# MCF5441x register map
Vendor: NXP; File version: 1.0
Registers are 32-bit, read-write, reset 0x0 unless marked. A register's access mark holds for its fields unless they carry their own. Offsets are from the block's base; [hi:lo] are bit positions; lines under a group give offsets from that group; {n}, {i} and the like mark numbered series.

## FLEXBUS
Base 0xFC008000
{0x0+0xC*i} CSAR{i} (i=0..5)
  [31:16] BA
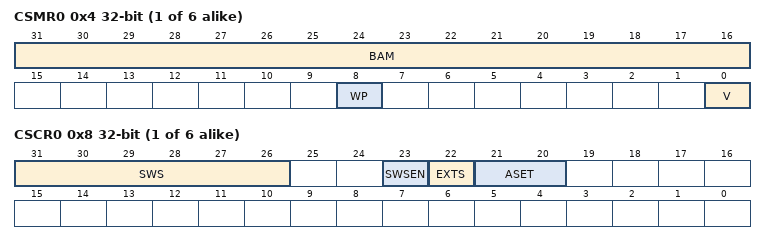
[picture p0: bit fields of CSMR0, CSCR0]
{0x4+0xC*i} CSMR{i} (i=0..5)
  [31:16] BAM
  [8] WP
  [0] V
    0=INVALID; 1=VALID
{0x8+0xC*i} CSCR{i} reset not defined (i=0..5)
  [31:26] SWS
  [23] SWSEN
  [22] EXTS
    0=ONE_CYCLE; 1=UNTIL_CS
  [21:20] ASET
    0=FIRST_EDGE; 1=SECOND_EDGE; 2=THIRD_EDGE; 3=FOURTH_EDGE

## FLEXCAN0
Base 0xFC020000
Same registers: FLEXCAN1 0xFC024000
0x00 CANMCR reset 0xD890000F
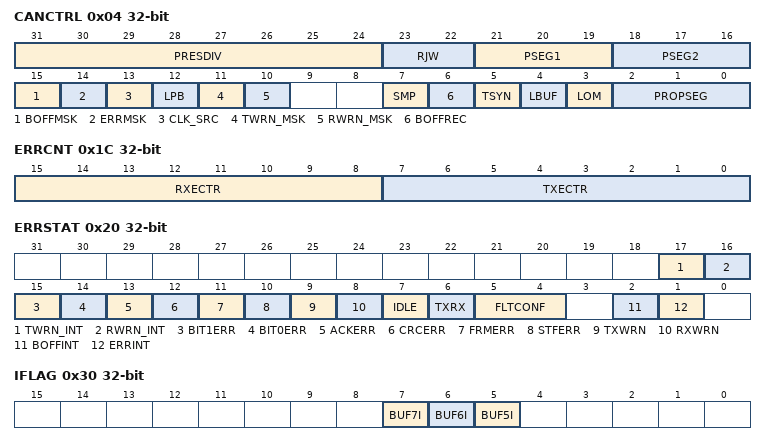
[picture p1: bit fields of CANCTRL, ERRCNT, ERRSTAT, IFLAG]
0x04 CANCTRL
  [31:24] PRESDIV
  [23:22] RJW
  [21:19] PSEG1
  [18:16] PSEG2
  [15] BOFFMSK
    0=DISABLED; 1=ENABLED
  [14] ERRMSK
    0=DISABLED; 1=ENABLED
  [13] CLK_SRC
  [12] LPB
    0=DISABLED; 1=ENABLED
  [11] TWRN_MSK
    0=DISABLED; 1=ENABLED
  [10] RWRN_MSK
    0=DISABLED; 1=ENABLED
  [7] SMP
  [6] BOFFREC
  [5] TSYN
    0=DISABLED; 1=ENABLED
  [4] LBUF
  [3] LOM
  [2:0] PROPSEG
0x08 TIMER
  [15:0] TIMER
0x10 RXGMASK reset 0x1FFFFFFF
0x14 RX14MASk reset 0x1FFFFFFF
0x18 RX15MASK reset 0x1FFFFFFF
0x1C ERRCNT
  [15:8] RXECTR, [7:0] TXECTR
0x20 ERRSTAT
  [17] TWRN_INT write-1-clears
  [16] RWRN_INT write-1-clears
  [15] BIT1ERR
  [14] BIT0ERR
  [13] ACKERR
  [12] CRCERR
  [11] FRMERR
  [10] STFERR
  [9] TXWRN
    0=TRANSMIT_ERROR_COUNTER_96; 1=TXERRCOUNTER_96
  [8] RXWRN
    0=RECEIVE_ERROR_COUNTER_96; 1=RXERRCOUNTER_96
  [7] IDLE
    0=NOT_IDLE; 1=IDLE
  [6] TXRX
  [5:4] FLTCONF
    0=ACTIVE; 1=PASSIVE
  [2] BOFFINT write-1-clears
  [1] ERRINT write-1-clears
    0=NO_ERROR; 1=ERROR
0x28 IMASK
  [15:0] BUFnM
0x30 IFLAG
  [7] BUF7I, [6] BUF6I, [5] BUF5I
{0x80+0x10*i} MB[{i}] (i=0..15) group — MB[{i}]
  0x00 CS reset not defined
  0x04 ID reset not defined
  0x08 DATA0 reset not defined
  0x0C DATA1 reset not defined
{0x880+4i} RXIMR[{i}] (i=0..15) reset not defined — RXIMR[{i}]

## I2C0
Base 0xFC058000
Same registers: I2C2 0xEC010000, I2C3 0xEC014000, I2C4 0xEC018000, I2C5 0xEC01C000, I2C1 0xFC038000
0x00 I2ADR 8-bit
  [7:1] ADR
0x04 I2FDR 8-bit
  [5:0] IC
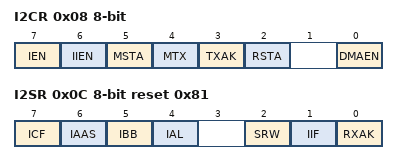
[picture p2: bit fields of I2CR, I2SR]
0x08 I2CR 8-bit
  [7] IEN
  [6] IIEN
    0=I; 1=IF_DMAEN_IS_CLEARED_I
  [5] MSTA
  [4] MTX
  [3] TXAK
  [2] RSTA
  [0] DMAEN
0x0C I2SR 8-bit reset 0x81
  [7] ICF, [6] IAAS, [5] IBB, [4] IAL, [2] SRW, [1] IIF, [0] RXAK
0x10 I2DR 8-bit
  [7:0] DATA read-has-side-effects

## IACK
Base 0xFC054000
0xE0 GSWIACK 8-bit ro
  [7:0] VECTOR
{0xE0+4i} GL{i}IACK 8-bit ro reset 0x18 (i=1..7)

## INTC0
Base 0xFC048000
0x00 IPRH ro
0x04 IPRL ro
  [31:0] INT
0x08 IMRH reset 0xFFFFFFFF
0x0C IMRL reset 0xFFFFFFFF
  [31:0] INT_MASK
0x10 INTFRCH
0x14 INTFRCL
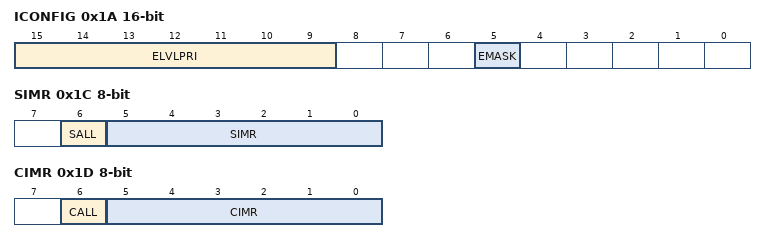
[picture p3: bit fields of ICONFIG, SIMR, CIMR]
0x1A ICONFIG 16-bit
  [15:9] ELVLPRI, [5] EMASK
0x1C SIMR 8-bit wo
  [6] SALL, [5:0] SIMR
0x1D CIMR 8-bit wo
  [6] CALL, [5:0] CIMR
0x1E CLMASK 8-bit reset 0xF
  [3:0] CLMASK
0x1F SLMASK 8-bit reset 0xF
  [3:0] SLMASK
{0x40+i} ICR{i} (i=0..63) 8-bit — ICR{i}
  [2:0] LEVEL
0xE0 SWIACK 8-bit ro
  [7:0] VECTOR
{0xE0+4i} L{i}IACK 8-bit ro reset 0x18 (i=1..7)

## INTC1
Base 0xFC04C000
Registers as INTC0, without ICONFIG, CLMASK, SLMASK.

## INTC2
Base 0xFC050000
Registers as INTC0, without ICONFIG, CLMASK, SLMASK; these are added or differ:
0xE0 SWIACK 8-bit ro

## MACNET0
Base 0xFC0D4000
Same registers: MACNET1 0xFC0D8000
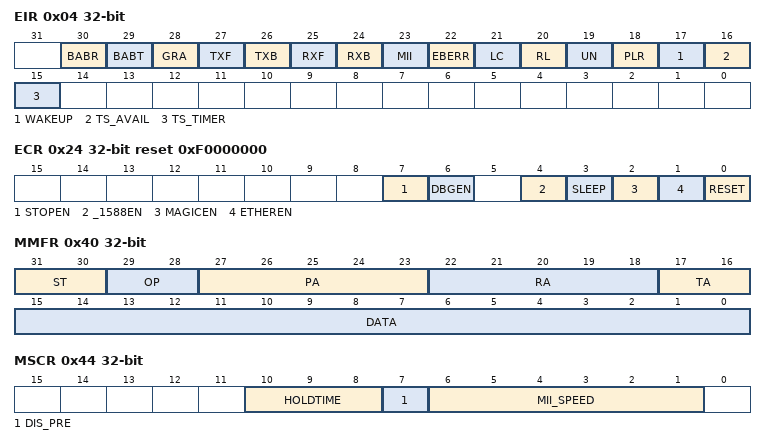
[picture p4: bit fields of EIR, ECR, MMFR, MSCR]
0x04 EIR
  [30] BABR write-1-clears, [29] BABT write-1-clears, [28] GRA write-1-clears, [27] TXF write-1-clears, [26] TXB write-1-clears, [25] RXF write-1-clears, [24] RXB write-1-clears, [23] MII write-1-clears, [22] EBERR write-1-clears, [21] LC write-1-clears, [20] RL write-1-clears, [19] UN write-1-clears, [18] PLR write-1-clears, [17] WAKEUP write-1-clears, [16] TS_AVAIL write-1-clears, [15] TS_TIMER write-1-clears
0x08 EIMR
0x10 RDAR
  [24] RDAR
0x14 TDAR
  [24] TDAR
0x24 ECR reset 0xF0000000
  [7] STOPEN
  [6] DBGEN
  [4] _1588EN
  [3] SLEEP
    0=NORMAL_OPERATING_MODE; 1=SLEEP_MODE
  [2] MAGICEN
  [1] ETHEREN
  [0] RESET
0x40 MMFR
  [31:30] ST, [29:28] OP, [27:23] PA, [22:18] RA, [17:16] TA, [15:0] DATA
0x44 MSCR
  [10:8] HOLDTIME, [7] DIS_PRE, [6:1] MII_SPEED
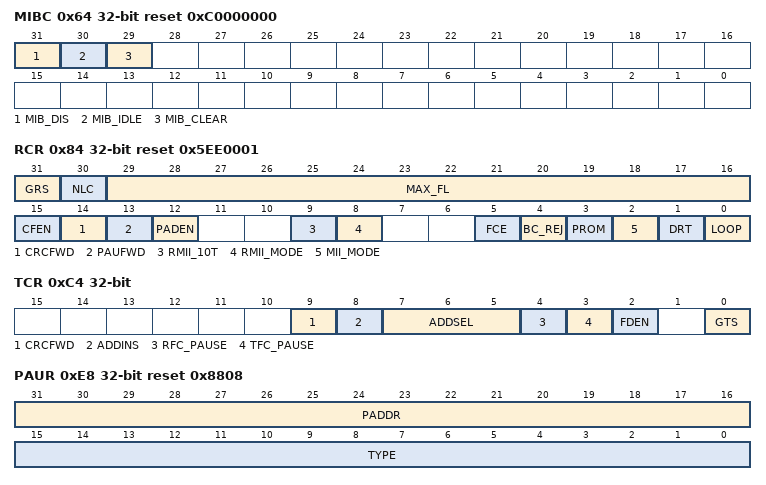
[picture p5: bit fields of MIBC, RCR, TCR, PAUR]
0x64 MIBC reset 0xC0000000
  [31] MIB_DIS, [30] MIB_IDLE, [29] MIB_CLEAR
0x84 RCR reset 0x5EE0001
  [31] GRS, [30] NLC, [29:16] MAX_FL, [15] CFEN, [14] CRCFWD, [13] PAUFWD, [12] PADEN, [9] RMII_10T, [8] RMII_MODE, [5] FCE, [4] BC_REJ, [3] PROM, [2] MII_MODE, [1] DRT, [0] LOOP
0xC4 TCR
  [9] CRCFWD, [8] ADDINS, [7:5] ADDSEL, [4] RFC_PAUSE, [3] TFC_PAUSE, [2] FDEN, [0] GTS
0xE4 PALR
0xE8 PAUR reset 0x8808
  [31:16] PADDR, [15:0] TYPE
0xEC OPD reset 0x10000
0x118 IAUR
0x11C IALR
0x120 GAUR
0x124 GALR
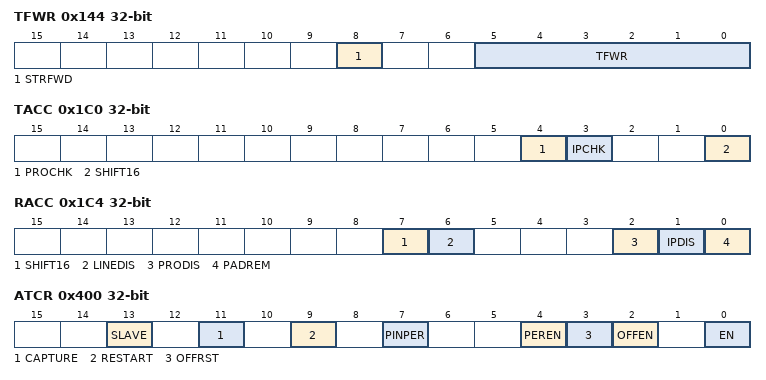
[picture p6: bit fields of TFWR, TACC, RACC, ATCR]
0x144 TFWR
  [8] STRFWD, [5:0] TFWR
0x14C FRBR ro reset 0x600
0x150 FRSR reset 0x500
0x180 RDSR
0x184 TDSR
0x188 MRBR
  [13:4] R_BUF_SIZE
0x190 RSFL
  [7:0] RX_SECTION_FULL
0x194 RSEM
  [7:0] RX_SECTION_EMPTY
0x198 RAEM reset 0x4
  [7:0] RX_ALMOST_EMPTY
0x19C RAFL reset 0x4
  [7:0] RX_ALMOST_FULL
0x1A0 TSEM
  [7:0] TX_SECTION_EMPTY
0x1A4 TAEM reset 0x4
  [7:0] TX_ALMOST_EMPTY
0x1A8 TAFL reset 0x8
  [7:0] TX_ALMOST_FULL
0x1AC TIPG reset 0xC
  [4:0] IPG
0x1B0 FTRL reset 0x7FF
  [13:0] TRUNC_FL
0x1C0 TACC
  [4] PROCHK, [3] IPCHK, [0] SHIFT16
0x1C4 RACC
  [7] SHIFT16, [6] LINEDIS, [2] PRODIS, [1] IPDIS, [0] PADREM
0x400 ATCR
  [13] SLAVE
  [11] CAPTURE
  [9] RESTART
  [7] PINPER
    0=DISABLE; 1=ENABLE
  [4] PEREN
  [3] OFFRST
  [2] OFFEN
  [0] EN
0x404 ATVR
  [31:0] ATIME
0x408 ATOFF
  [31:0] OFFSET
0x40C ATPER reset 0x3B9ACA00
0x410 ATCOR
  [30:0] COR
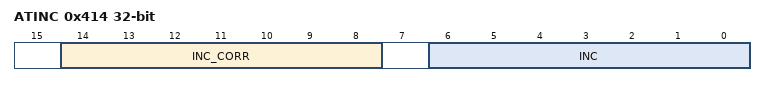
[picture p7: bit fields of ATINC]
0x414 ATINC
  [14:8] INC_CORR, [6:0] INC
0x418 ATSTMP ro
{0x500+8i} SMACL{i} reset not defined (i=0..3)
  [31:0] SMACL
{0x504+8i} SMACU{i} reset not defined (i=0..3)
  [31:16] SMACH
